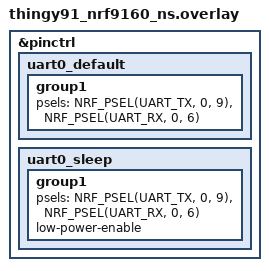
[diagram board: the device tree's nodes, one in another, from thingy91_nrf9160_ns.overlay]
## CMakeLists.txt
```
#
# Copyright (c) 2019 Nordic Semiconductor
#
# SPDX-License-Identifier: LicenseRef-Nordic-5-Clause
#

cmake_minimum_required(VERSION 3.20.0)

find_package(Zephyr REQUIRED HINTS $ENV{ZEPHYR_BASE})
project(gnss_sample)

zephyr_library_sources(src/main.c)

add_subdirectory(src/gnss_assistance)
add_subdirectory(src/gnss)
add_subdirectory(src/modem)
add_subdirectory(src/general_lib)
add_subdirectory(src/json)
add_subdirectory(src/AWS)
add_subdirectory(src/accelerometer)
add_subdirectory(src/timer)
add_subdirectory(src/shell)
add_subdirectory(src/Battery_managment)
```

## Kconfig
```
#
# Copyright (c) 2020 Nordic Semiconductor ASA
#
# SPDX-License-Identifier: LicenseRef-Nordic-5-Clause
#

menu "GNSS sample"

choice
	default GNSS_SAMPLE_MODE_CONTINUOUS
	prompt "Select GNSS operation mode"

config GNSS_SAMPLE_MODE_CONTINUOUS
	bool "Continuous tracking"

config GNSS_SAMPLE_MODE_PERIODIC
	bool "Periodic fixes"

config GNSS_SAMPLE_MODE_TTFF_TEST
	bool "Time-to-first-fix (TTFF) test mode"
	select GNSS_SAMPLE_NMEA_ONLY

endchoice

if GNSS_SAMPLE_MODE_PERIODIC

config GNSS_SAMPLE_PERIODIC_INTERVAL
	int "Fix interval for periodic fixes"
	range 10 65535
	default 120
	help
	  Fix interval (in seconds) for periodic fixes.

config GNSS_SAMPLE_PERIODIC_TIMEOUT
	int "Fix timeout for periodic fixes"
	range 0 65535
	default 120
	help
	  Fix timeout (in seconds) for periodic fixes.
	  If set to zero, GNSS is allowed to run indefinitely until a valid PVT estimate is produced.

endif # GNSS_SAMPLE_MODE_PERIODIC

if GNSS_SAMPLE_MODE_TTFF_TEST

config GNSS_SAMPLE_MODE_TTFF_TEST_COLD_START
	bool "Delete GNSS data before each start (cold start)"
	help
	  When enabled, deletes all stored data from GNSS to force a cold start every time GNSS is started.

config GNSS_SAMPLE_MODE_TTFF_TEST_INTERVAL
	int "Time to wait between TTFF tests in seconds"
	range 1 604800
	default 120

endif # GNSS_SAMPLE_MODE_TTFF_TEST

config GNSS_SAMPLE_NMEA_ONLY
	bool "Output only NMEA strings"
	help
	  Outputs only NMEA strings from the GNSS.

endmenu

choice
	default GNSS_SAMPLE_ASSISTANCE_NONE
	prompt "Select whether GNSS assistance is used or not"

config GNSS_SAMPLE_ASSISTANCE_NONE
	bool "Assistance not used"

config GNSS_SAMPLE_ASSISTANCE_NRF_CLOUD
	bool "Use nRF Cloud A-GPS or P-GPS"
	select NRF_CLOUD_REST
	imply NRF_CLOUD_AGPS
	select MODEM_JWT
	select MODEM_INFO
	select DATE_TIME

config GNSS_SAMPLE_ASSISTANCE_SUPL
	bool "Use SUPL A-GPS"
	select SUPL_CLIENT_LIB

config GNSS_SAMPLE_ASSISTANCE_MINIMAL
	bool "Use factory almanac, LTE network time and MCC based location"
	select GNSS_SAMPLE_LTE_ON_DEMAND
	select SETTINGS
	select FCB
	select FLASH
	select FLASH_MAP

endchoice

if !GNSS_SAMPLE_ASSISTANCE_NONE

config GNSS_SAMPLE_LTE_ON_DEMAND
	bool "LTE is activated only when needed to fetch A-GPS data"
	depends on !NRF_CLOUD_PGPS
	help
	  Activates LTE only when it is needed to fetch A-GPS data. This is not supported when
	  P-GPS is enabled.

endif # !GNSS_SAMPLE_ASSISTANCE_NONE

if GNSS_SAMPLE_ASSISTANCE_SUPL

config GNSS_SAMPLE_SUPL_HOSTNAME
	string "SUPL server hostname"
	help
	  SUPL server hostname.

config GNSS_SAMPLE_SUPL_PORT
	int "SUPL server port number"
	range 0 65535
	default 7276
	help
	  SUPL server port number.

endif # GNSS_SAMPLE_ASSISTANCE_SUPL

if GNSS_SAMPLE_MODE_CONTINUOUS

choice
	default GNSS_SAMPLE_POWER_SAVING_DISABLED
	prompt "Select GNSS power saving mode (duty-cycling)"

config GNSS_SAMPLE_POWER_SAVING_DISABLED
	bool "No power saving"

config GNSS_SAMPLE_POWER_SAVING_MODERATE
	bool "Power saving without significant performance degradation"

config GNSS_SAMPLE_POWER_SAVING_HIGH
	bool "Power saving with acceptable performance degradation"

endchoice

endif # GNSS_SAMPLE_MODE_CONTINUOUS

config GNSS_SAMPLE_REFERENCE_LATITUDE
	string "Reference position latitude in decimal degrees"
	help
	  When set, the sample calculates the distance from the reference position for each fix.
	  Given in decimal degrees (DD), for example "61.500000".

config GNSS_SAMPLE_REFERENCE_LONGITUDE
	string "Reference position longitude in decimal degrees"
	help
	  When set, the sample calculates the distance from the reference position for each fix.
	  Given in decimal degrees (DD), for example "23.800000".

config GNSS_SAMPLE_LOW_ACCURACY
	bool "Allow low accuracy fixes"
	help
	  Allows fixes with lower accuracy.

if GNSS_SAMPLE_ASSISTANCE_MINIMAL && GNSS_SAMPLE_LOW_ACCURACY

config GNSS_SAMPLE_ASSISTANCE_REFERENCE_ALT
	int "Reference altitude for 3-sat first fix in meters"
	range -32767 32767
	default -32767
	help
	  Reference altitude for 3-sat first fix in meters above the reference ellipsoid surface.
	  The default value -32767 implies that reference altitude is not injected.

endif # GNSS_SAMPLE_ASSISTANCE_MINIMAL && GNSS_SAMPLE_LOW_ACCURACY
menu "AWS IoT Sample Settings"

config APP_VERSION
	string "Application version"
	default "v1.0.0"

config PUBLICATION_INTERVAL_SECONDS
	int "Interval in seconds that the sample will publish data"
	default 60

config CONNECTION_RETRY_TIMEOUT_SECONDS
	int "Number of seconds between each AWS IoT connection retry"
	default 30

endmenu

menu "Zephyr Kernel"
source "Kconfig.zephyr"
endmenu

module = GNSS_SAMPLE
module-str = GNSS sample
source "${ZEPHYR_BASE}/subsys/logging/Kconfig.template.log_config"
```

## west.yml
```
manifest:
  remotes:
    - name: ncs
      url-base: https://github.com/nrfconnect
  projects:
    - name: sdk-nrf
      remote: ncs
      path: nrf
      revision: v2.2.0
      import: true
      clone-depth: 1
  self:
    path: tracker_fw
```

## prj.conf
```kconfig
#
# Copyright (c) 2019 Nordic Semiconductor ASA
#
# SPDX-License-Identifier: LicenseRef-Nordic-5-Clause
#
CONFIG_APP_VERSION="0.1.2"
# General config
CONFIG_FPU=y
CONFIG_POLL=y
CONFIG_STDOUT_CONSOLE=y
CONFIG_UART_INTERRUPT_DRIVEN=y
CONFIG_NEWLIB_LIBC=y
CONFIG_NEWLIB_LIBC_FLOAT_PRINTF=y
CONFIG_LOG_MODE_IMMEDIATE=y
CONFIG_DATE_TIME=y

CONFIG_ASSERT=y
# modem 
CONFIG_NRF_MODEM_LIB=y
CONFIG_MODEM_INFO=y
# CONFIG_MODEM_ANTENNA="AT%XMAGPIO=1,0,0,1,1,1574,1577"
CONFIG_MODEM_ANTENNA_GNSS_EXTERNAL=y
# LTE Link Control
CONFIG_LTE_LINK_CONTROL=y
CONFIG_LTE_NETWORK_MODE_LTE_M_GPS=y
# Request eDRX from the network
CONFIG_LTE_EDRX_REQ=y
# PSM requested periodic TAU 8 hours
CONFIG_LTE_PSM_REQ_RPTAU="00101000"
# PSM requested active time 6 seconds
CONFIG_LTE_PSM_REQ_RAT="00000011"
# Auto-connect should be left off as we want the application to control LTE
CONFIG_LTE_AUTO_INIT_AND_CONNECT=n
# AT Host library - Used to send AT commands directy from an UART terminal and to allow
#		    integration with nRF Connect for Desktop LTE Link monitor application.
CONFIG_AT_HOST_LIBRARY=y


# Console
CONFIG_CONSOLE=y
CONFIG_UART_CONSOLE=n

CONFIG_RTT_CONSOLE=y
CONFIG_USE_SEGGER_RTT=y                            # DISABLE IF NO DEBUGGER
CONFIG_SEGGER_RTT_MAX_NUM_UP_BUFFERS=2
CONFIG_SEGGER_RTT_MAX_NUM_DOWN_BUFFERS=2
CONFIG_SEGGER_RTT_BUFFER_SIZE_UP=2048
CONFIG_SEGGER_RTT_BUFFER_SIZE_DOWN=2048
CONFIG_LOG_PROCESS_THREAD_STACK_SIZE=2048

# GNSS 
# AGPS
CONFIG_GNSS_SAMPLE_ASSISTANCE_NRF_CLOUD=n
CONFIG_GNSS_SAMPLE_ASSISTANCE_SUPL=y
CONFIG_GNSS_SAMPLE_SUPL_HOSTNAME="supl.google.com"
CONFIG_GNSS_SAMPLE_SUPL_PORT=7276
CONFIG_SUPL_CLIENT_LIB=y
CONFIG_GNSS_SAMPLE_LOW_ACCURACY=n

# Networking
CONFIG_NETWORKING=y
CONFIG_NET_SOCKETS_OFFLOAD=y
CONFIG_NET_SOCKETS=y
CONFIG_NET_SOCKETS_POSIX_NAMES=y
# Disable native network stack to save some memory
CONFIG_NET_NATIVE=n

# Memory and stack configuration
CONFIG_HEAP_MEM_POOL_SIZE=16384
CONFIG_MAIN_STACK_SIZE=16384
CONFIG_SYSTEM_WORKQUEUE_STACK_SIZE=1536

# CJSON
CONFIG_CJSON_LIB=y

# AWS IoT library
CONFIG_AWS_IOT=y
CONFIG_AWS_IOT_CLIENT_ID_STATIC="351358815047250"
CONFIG_AWS_IOT_BROKER_HOST_NAME="a3upctgsstkllp-ats.iot.eu-west-1.amazonaws.com"
CONFIG_AWS_IOT_PORT=8883
CONFIG_AWS_IOT_SEC_TAG=42
CONFIG_AWS_IOT_APP_SUBSCRIPTION_LIST_COUNT=2
CONFIG_AWS_IOT_TOPIC_UPDATE_DELTA_SUBSCRIBE=y
CONFIG_AWS_IOT_LAST_WILL=y
CONFIG_AWS_IOT_TOPIC_GET_ACCEPTED_SUBSCRIBE=y
CONFIG_AWS_IOT_TOPIC_GET_REJECTED_SUBSCRIBE=y
CONFIG_PUBLICATION_INTERVAL_SECONDS=20
CONFIG_CONNECTION_RETRY_TIMEOUT_SECONDS=60
# MQTT - Maximum MQTT keepalive timeout specified by AWS IoT Core
CONFIG_MQTT_KEEPALIVE=1200

# Accelerometer
CONFIG_I2C=y
CONFIG_SENSOR=y
CONFIG_LIS2DH=y
CONFIG_LIS2DH_ACCEL_RANGE_16G=y
CONFIG_LIS2DH_ODR_8=y
CONFIG_LIS2DH_TRIGGER_GLOBAL_THREAD=y

# Shell and cert
CONFIG_MODEM_INFO=y
CONFIG_MODEM_KEY_MGMT=y
CONFIG_SHELL=y
CONFIG_SHELL_BACKEND_RTT=y                          # DISABLE IF NO DEBUGGER Used for write through RTT
CONFIG_SHELL_BACKEND_DUMMY=n                        # ENABLE IF NO DEBUGGER
CONFIG_SHELL_BACKEND_SERIAL=n
CONFIG_SHELL_ECHO_STATUS=n
CONFIG_SHELL_PROMPT_RTT="rtt"
CONFIG_SHELL_ARGC_MAX=32
CONFIG_SHELL_CMD_BUFF_SIZE=1800
CONFIG_SHELL_HISTORY=n

# Battery voltage
CONFIG_ADC=y

# AWS FOTA
CONFIG_DOWNLOAD_CLIENT=y
CONFIG_AWS_FOTA=y
CONFIG_FOTA_DOWNLOAD=y
CONFIG_DFU_TARGET=y
CONFIG_NOTIFY=y



# Download client (needed by AWS FOTA)
CONFIG_DOWNLOAD_CLIENT=y
CONFIG_DOWNLOAD_CLIENT_STACK_SIZE=4096
CONFIG_NET_SOCKETS_LOG_LEVEL_DBG=y
CONFIG_AWS_IOT_MQTT_PAYLOAD_BUFFER_LEN=2048
CONFIG_AWS_IOT_MQTT_RX_TX_BUFFER_LEN=4069

# MCUBOOT
CONFIG_BOOTLOADER_MCUBOOT=y
CONFIG_MCUBOOT_IMG_MANAGER=y
CONFIG_REBOOT=y

# Image manager
CONFIG_IMG_MANAGER=y
CONFIG_STREAM_FLASH=y
CONFIG_FLASH_MAP=y
CONFIG_FLASH=y
CONFIG_IMG_ERASE_PROGRESSIVELY=y
```

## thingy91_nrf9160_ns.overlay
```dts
// To get started, press Ctrl+Space to bring up the completion menu and view the available nodes.

// You can also use the buttons in the sidebar to perform actions on nodes.
// Actions currently available include:

// * Enabling / disabling the node
// * Adding the bus to a bus
// * Removing the node
// * Connecting ADC channels

// For more help, browse the DeviceTree documentation at https://docs.zephyrproject.org/latest/guides/dts/index.html
// You can also visit the nRF DeviceTree extension documentation at https://nrfconnect.github.io/vscode-nrf-connect/devicetree/nrfdevicetree.html
&pinctrl {
	uart0_default: uart0_default {
		group1 {
			psels = <NRF_PSEL(UART_TX, 0, 9)>,
				<NRF_PSEL(UART_RX, 0, 6)>;
		};
	};

	uart0_sleep: uart0_sleep {
		group1 {
			psels = <NRF_PSEL(UART_TX, 0, 9)>,
				<NRF_PSEL(UART_RX, 0, 6)>;
			low-power-enable;
		};
	};
};
```

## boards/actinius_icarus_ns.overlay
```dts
&charger_enable {
    charger = "auto";
};
```

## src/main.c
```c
/*
 * Copyright (c) 2019 Nordic Semiconductor ASA
 *
 * SPDX-License-Identifier: LicenseRef-Nordic-5-Clause
 */

#include "general_include.h"
#include "modem.h"
#include "timer.h"
LOG_MODULE_REGISTER(gnss_sample, CONFIG_GNSS_SAMPLE_LOG_LEVEL);


BUILD_ASSERT(IS_ENABLED(CONFIG_LTE_NETWORK_MODE_LTE_M_GPS) ||
	     IS_ENABLED(CONFIG_LTE_NETWORK_MODE_NBIOT_GPS) ||
	     IS_ENABLED(CONFIG_LTE_NETWORK_MODE_LTE_M_NBIOT_GPS),
	     "CONFIG_LTE_NETWORK_MODE_LTE_M_GPS, "
	     "CONFIG_LTE_NETWORK_MODE_NBIOT_GPS or "
	     "CONFIG_LTE_NETWORK_MODE_LTE_M_NBIOT_GPS must be enabled");

BUILD_ASSERT((sizeof(CONFIG_GNSS_SAMPLE_REFERENCE_LATITUDE) == 1 &&
	      sizeof(CONFIG_GNSS_SAMPLE_REFERENCE_LONGITUDE) == 1) ||
	     (sizeof(CONFIG_GNSS_SAMPLE_REFERENCE_LATITUDE) > 1 &&
	      sizeof(CONFIG_GNSS_SAMPLE_REFERENCE_LONGITUDE) > 1),
	     "CONFIG_GNSS_SAMPLE_REFERENCE_LATITUDE and "
	     "CONFIG_GNSS_SAMPLE_REFERENCE_LONGITUDE must be both either set or empty");


int main(void)
{

	timer_init();
	printf("Starting moto tracker\n");
	init_adc();
	k_sleep(K_FOREVER);
	return 0;
}
```
